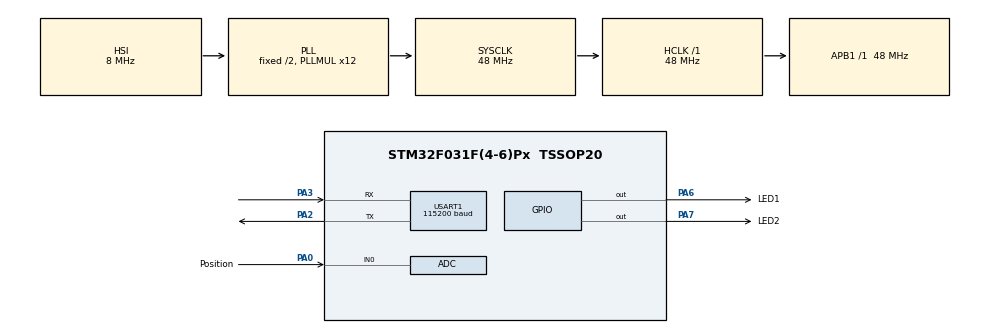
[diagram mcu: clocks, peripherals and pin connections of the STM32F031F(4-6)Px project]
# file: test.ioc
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ADC.ClockPrescaler=ADC_CLOCK_ASYNC_DIV1
ADC.ContinuousConvMode=ENABLE
ADC.DiscontinuousConvMode=DISABLE
ADC.Resolution=ADC_RESOLUTION_8B
ADC.SamplingTime=ADC_SAMPLETIME_239CYCLES_5
Mcu.Family=STM32F0
Mcu.Name=STM32F031F(4-6)Px
Mcu.Package=TSSOP20
NVIC.USART1_IRQn=true\:0\:0\:false\:false\:true\:true\:true\:true
PA0.GPIO_Label=Position
PA0.Mode=IN0
PA0.Signal=ADC_IN0
PA13.Mode=Serial_Wire
PA13.Signal=SYS_SWDIO
PA14.Mode=Serial_Wire
PA14.Signal=SYS_SWCLK
PA2.Mode=Asynchronous
PA2.Signal=USART1_TX
PA3.Mode=Asynchronous
PA3.Signal=USART1_RX
PA6.GPIO_Label=LED1
PA6.Signal=GPIO_Output
PA7.GPIO_Label=LED2
PA7.Signal=GPIO_Output
ProjectManager.HeapSize=0x200
ProjectManager.StackSize=0x400
ProjectManager.TargetToolchain=Makefile
RCC.AHBFreq_Value=48000000
RCC.APB1Freq_Value=48000000
RCC.APB1TimFreq_Value=48000000
RCC.HCLKFreq_Value=48000000
RCC.PLLMUL=RCC_PLL_MUL12
RCC.SYSCLKFreq_VALUE=48000000
RCC.SYSCLKSource=RCC_SYSCLKSOURCE_PLLCLK
USART1.BaudRate=115200
USART1.VirtualMode-Asynchronous=VM_ASYNC
board=custom

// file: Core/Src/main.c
/* USER CODE BEGIN Header */
/**
  ******************************************************************************
  * @file           : main.c
  * @brief          : Main program body
  ******************************************************************************
  * @attention
  *
  * Copyright (c) 2024 STMicroelectronics.
  * All rights reserved.
  *
  * This software is licensed under terms that can be found in the LICENSE file
  * in the root directory of this software component.
  * If no LICENSE file comes with this software, it is provided AS-IS.
  *
  ******************************************************************************
  */
/* USER CODE END Header */
#include "main.h"
#include "adc.h"
#include "usart.h"
#include "gpio.h"

/* USER CODE BEGIN Includes */
#include <stdio.h>
#include <string.h>
/* USER CODE END Includes */

void SystemClock_Config(void);

/* USER CODE BEGIN 0 */
uint16_t potVal;
char data[20];
/* USER CODE END 0 */

int main(void)
{

  /* MCU Configuration--------------------------------------------------------*/

  /* Reset of all peripherals, Initializes the Flash interface and the Systick. */
  HAL_Init();

  /* Configure the system clock */
  SystemClock_Config();

  /* Initialize all configured peripherals */
  MX_GPIO_Init();
  MX_USART1_UART_Init();
  MX_ADC_Init();

  /* Infinite loop */
  while (1)
  {

    /* USER CODE BEGIN 3 */

    HAL_ADC_Start(&hadc);
    HAL_ADC_PollForConversion(&hadc,100);
    potVal=HAL_ADC_GetValue(&hadc);

    sprintf(data," ADC Value = %d \n\r", potVal);
    HAL_UART_Transmit(&huart1,(uint8_t*)data, strlen(data),1000);

    HAL_Delay(100);

  }
  /* USER CODE END 3 */
}

void SystemClock_Config(void)
{
  RCC_OscInitTypeDef RCC_OscInitStruct = {0};
  RCC_ClkInitTypeDef RCC_ClkInitStruct = {0};
  RCC_PeriphCLKInitTypeDef PeriphClkInit = {0};

  /** Initializes the RCC Oscillators according to the specified parameters
  * in the RCC_OscInitTypeDef structure.
  */
  RCC_OscInitStruct.OscillatorType = RCC_OSCILLATORTYPE_HSI|RCC_OSCILLATORTYPE_HSI14;
  RCC_OscInitStruct.HSIState = RCC_HSI_ON;
  RCC_OscInitStruct.HSI14State = RCC_HSI14_ON;
  RCC_OscInitStruct.HSICalibrationValue = RCC_HSICALIBRATION_DEFAULT;
  RCC_OscInitStruct.HSI14CalibrationValue = 16;
  RCC_OscInitStruct.PLL.PLLState = RCC_PLL_ON;
  RCC_OscInitStruct.PLL.PLLSource = RCC_PLLSOURCE_HSI;
  RCC_OscInitStruct.PLL.PLLMUL = RCC_PLL_MUL12;
  RCC_OscInitStruct.PLL.PREDIV = RCC_PREDIV_DIV1;
  if (HAL_RCC_OscConfig(&RCC_OscInitStruct) != HAL_OK)
  {
    Error_Handler();
  }

  /** Initializes the CPU, AHB and APB buses clocks
  */
  RCC_ClkInitStruct.ClockType = RCC_CLOCKTYPE_HCLK|RCC_CLOCKTYPE_SYSCLK
                              |RCC_CLOCKTYPE_PCLK1;
  RCC_ClkInitStruct.SYSCLKSource = RCC_SYSCLKSOURCE_PLLCLK;
  RCC_ClkInitStruct.AHBCLKDivider = RCC_SYSCLK_DIV1;
  RCC_ClkInitStruct.APB1CLKDivider = RCC_HCLK_DIV1;

  if (HAL_RCC_ClockConfig(&RCC_ClkInitStruct, FLASH_LATENCY_1) != HAL_OK)
  {
    Error_Handler();
  }
  PeriphClkInit.PeriphClockSelection = RCC_PERIPHCLK_USART1;
  PeriphClkInit.Usart1ClockSelection = RCC_USART1CLKSOURCE_PCLK1;
  if (HAL_RCCEx_PeriphCLKConfig(&PeriphClkInit) != HAL_OK)
  {
    Error_Handler();
  }
}

void Error_Handler(void)
{
  __disable_irq();
  while (1)
  {
  }
}
